VERSION ""

NS_ :

BS_:

BU_: VCU

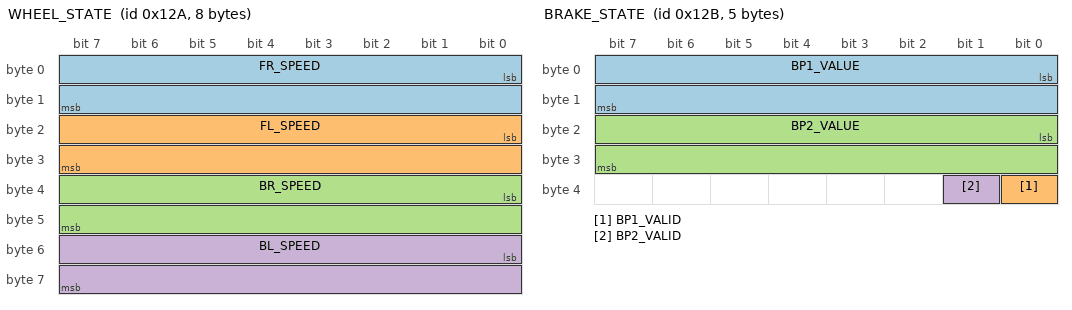
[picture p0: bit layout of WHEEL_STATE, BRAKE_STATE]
BO_ 298 WHEEL_STATE: 8 VCU
 SG_ FR_SPEED : 0|16@1- (0.01,0) [-100|100] "m/s" Vector__XXX
 SG_ FL_SPEED : 16|16@1- (0.01,0) [-100|100] "m/s" Vector__XXX
 SG_ BR_SPEED : 32|16@1- (0.01,0) [-100|100] "m/s" Vector__XXX
 SG_ BL_SPEED : 48|16@1- (0.01,0) [-100|100] "m/s" Vector__XXX

BO_ 299 BRAKE_STATE: 5 VCU
 SG_ BP1_VALUE : 0|16@1+ (0.1,0) [0|2000] "psi" Vector__XXX
 SG_ BP1_VALID : 32|1@1+ (1,0) [0|1] "" Vector__XXX
 SG_ BP2_VALUE : 16|16@1+ (0.1,0) [0|2000] "psi" Vector__XXX
 SG_ BP2_VALID : 33|1@1+ (1,0) [0|0] "" Vector__XXX

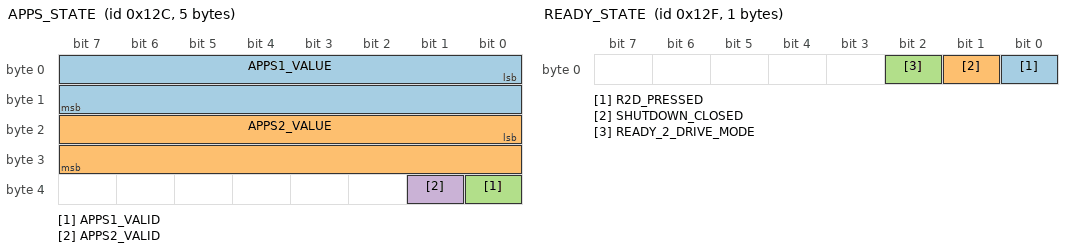
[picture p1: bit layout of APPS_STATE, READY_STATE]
BO_ 300 APPS_STATE: 5 VCU
 SG_ APPS1_VALUE : 0|16@1+ (0.1,0) [0|100] "" Vector__XXX
 SG_ APPS2_VALUE : 16|16@1+ (0.1,0) [0|100] "" Vector__XXX
 SG_ APPS1_VALID : 32|1@1+ (1,0) [0|1] "" Vector__XXX
 SG_ APPS2_VALID : 33|1@1+ (1,0) [0|1] "" Vector__XXX

BO_ 303 READY_STATE: 1 VCU
 SG_ R2D_PRESSED : 0|1@1+ (1,0) [0|1] "" Vector__XXX
 SG_ SHUTDOWN_CLOSED : 1|1@1+ (1,0) [0|1] "" Vector__XXX
 SG_ READY_2_DRIVE_MODE : 2|1@1+ (1,0) [0|1] "" Vector__XXX

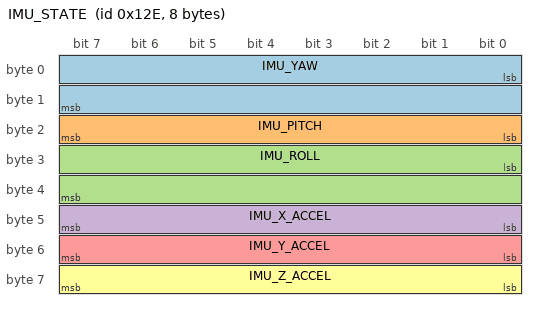
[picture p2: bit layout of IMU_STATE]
BO_ 302 IMU_STATE: 8 VCU
 SG_ IMU_YAW : 0|16@1- (1,0) [-180|180] "degrees" Vector__XXX
 SG_ IMU_PITCH : 16|8@1- (1,0) [-90|90] "degrees" Vector__XXX
 SG_ IMU_ROLL : 24|16@1- (1,0) [-180|180] "degrees" Vector__XXX
 SG_ IMU_X_ACCEL : 40|8@1- (0.1,0) [-12.8|12.7] "g" Vector__XXX
 SG_ IMU_Y_ACCEL : 48|8@1- (0.1,0) [-12.8|12.7] "g" Vector__XXX
 SG_ IMU_Z_ACCEL : 56|8@1- (0.1,0) [-12.8|12.7] "g" Vector__XXX

CM_ SG_ 303 READY_2_DRIVE_MODE "1 = ready
0 = idle";
